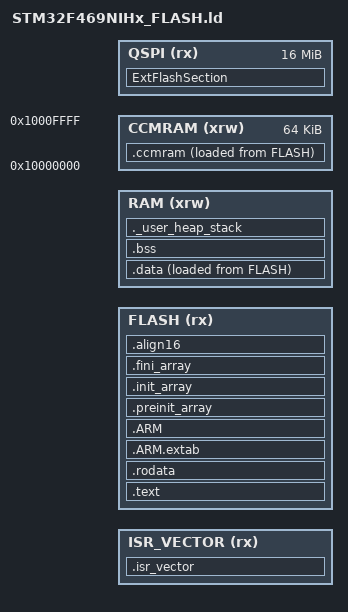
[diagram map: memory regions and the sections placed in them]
/*
*****************************************************************************
**

**  File        : LinkerScript.ld
**
**  Abstract    : Linker script for STM32F469NIHx Device with
**                2048KByte FLASH, 256KByte RAM
**
**                Set heap size, stack size and stack location according
**                to application requirements.
**
**                Set memory bank area and size if external memory is used.
**
**  Target      : STMicroelectronics STM32
**
**
**  Distribution: The file is distributed as is, without any warranty
**                of any kind.
**
**  (c)Copyright Ac6.
**  You may use this file as-is or modify it according to the needs of your
**  project. Distribution of this file (unmodified or modified) is not
**  permitted. Ac6 permit registered System Workbench for MCU users the
**  rights to distribute the assembled, compiled & linked contents of this
**  file as part of an application binary file, provided that it is built
**  using the System Workbench for MCU toolchain.
**
*****************************************************************************
*/

/* Entry Point */
ENTRY(Reset_Handler)

INCLUDE stm32-secure-patching-bootloader-linker-gcc_DISCO-F469I_v1.4.0.ld

/* Highest address of the user mode stack */
_estack = STM32_SECURE_PATCHING_BOOTLOADER_RAM_TOP;    /* end of RAM */
/* Generate a link error if heap and stack don't fit into RAM */
_Min_Heap_Size = 0x200;      /* required amount of heap  */
_Min_Stack_Size = 0x400; /* required amount of stack */

/* Specific ROM/RAM UserApp definition */
APPLI_region_intvec_start__  = STM32_SECURE_PATCHING_BOOTLOADER_SLOT0_START + 0x200;
APPLI_region_ROM_start    = STM32_SECURE_PATCHING_BOOTLOADER_SLOT0_START  + VECTOR_SIZE + 0x200;
APPLI_region_ROM_length   = STM32_SECURE_PATCHING_BOOTLOADER_SLOT0_END - APPLI_region_ROM_start + 1;
APPLI_region_RAM_start    = STM32_SECURE_PATCHING_BOOTLOADER_RAM_START;
APPLI_region_RAM_length    = STM32_SECURE_PATCHING_BOOTLOADER_RAM_TOP - APPLI_region_RAM_start;

/* Specify the memory areas */
MEMORY
{
ISR_VECTOR (rx)   : ORIGIN = APPLI_region_intvec_start__, LENGTH = VECTOR_SIZE
FLASH (rx)      : ORIGIN = APPLI_region_ROM_start, LENGTH = APPLI_region_ROM_length
RAM (xrw)      : ORIGIN = APPLI_region_RAM_start, LENGTH = APPLI_region_RAM_length
CCMRAM (xrw)      : ORIGIN = 0x10000000, LENGTH = 64K
QSPI (rx)         : ORIGIN = STM32_SECURE_PATCHING_BOOTLOADER_MULTISEG_START, LENGTH = 16M
}

/* Define output sections */
SECTIONS
{
  /* The startup code goes first into FLASH */
  .isr_vector :
  {
    . = ALIGN(8);
    KEEP(*(.isr_vector)) /* Startup code */
    FILL(0);
    . = ORIGIN(ISR_VECTOR) + LENGTH(ISR_VECTOR) - 1;
    BYTE(0)
    . = ALIGN(8);
  } >ISR_VECTOR

  /* The program code and other data goes into FLASH */
  .text :
  {
    . = ALIGN(4);
    *(.text)           /* .text sections (code) */
    *(.text*)          /* .text* sections (code) */
    *(.glue_7)         /* glue arm to thumb code */
    *(.glue_7t)        /* glue thumb to arm code */
    *(.eh_frame)

    KEEP (*(.init))
    KEEP (*(.fini))

    . = ALIGN(4);
    _etext = .;        /* define a global symbols at end of code */
  } >FLASH

  /* Constant data goes into FLASH */
  .rodata :
  {
    . = ALIGN(4);
    *(.rodata)         /* .rodata sections (constants, strings, etc.) */
    *(.rodata*)        /* .rodata* sections (constants, strings, etc.) */
    . = ALIGN(4);
  } >FLASH

  .ARM.extab   : { *(.ARM.extab* .gnu.linkonce.armextab.*) } >FLASH
  .ARM : {
    __exidx_start = .;
    *(.ARM.exidx*)
    __exidx_end = .;
  } >FLASH

  .preinit_array     :
  {
    PROVIDE_HIDDEN (__preinit_array_start = .);
    KEEP (*(.preinit_array*))
    PROVIDE_HIDDEN (__preinit_array_end = .);
  } >FLASH
  .init_array :
  {
    PROVIDE_HIDDEN (__init_array_start = .);
    KEEP (*(SORT(.init_array.*)))
    KEEP (*(.init_array*))
    PROVIDE_HIDDEN (__init_array_end = .);
  } >FLASH
  .fini_array :
  {
    PROVIDE_HIDDEN (__fini_array_start = .);
    KEEP (*(SORT(.fini_array.*)))
    KEEP (*(.fini_array*))
    PROVIDE_HIDDEN (__fini_array_end = .);
  } >FLASH

  /* used by the startup to initialize data */
  _sidata = LOADADDR(.data);

  /* Initialized data sections goes into RAM, load LMA copy after code */
  .data : 
  {
    . = ALIGN(4);
    _sdata = .;        /* create a global symbol at data start */
    *(.data)           /* .data sections */
    *(.data*)          /* .data* sections */

    . = ALIGN(4);
    _edata = .;        /* define a global symbol at data end */
  } >RAM AT> FLASH

  _siccmram = LOADADDR(.ccmram);

  /* CCM-RAM section 
  * 
  * IMPORTANT NOTE! 
  * If initialized variables will be placed in this section,
  * the startup code needs to be modified to copy the init-values.  
  */
  .ccmram :
  {
    . = ALIGN(4);
    _sccmram = .;       /* create a global symbol at ccmram start */
    *(.ccmram)
    *(.ccmram*)
    
    . = ALIGN(4);
    _eccmram = .;       /* create a global symbol at ccmram end */
  } >CCMRAM AT> FLASH

   /* Extra ROM section (last one) to make sure the binary size is a multiple of the AES block size (16 bytes) */
  .align16 :
  {
    . = . + 1;         /* _edata=. is aligned on 8 bytes so could be aligned on 16 bytes: add 1 byte gap */
    . = ALIGN(16) - 1; /* increment the location counter until next 16 bytes aligned address (-1 byte)   */
    BYTE(0);           /* allocate 1 byte (value is 0) to be a multiple of 16 bytes                      */
  } > FLASH
  
  /* Uninitialized data section */
  . = ALIGN(4);
  .bss :
  {
    /* This is used by the startup in order to initialize the .bss section */
    _sbss = .;         /* define a global symbol at bss start */
    __bss_start__ = _sbss;
    *(.bss)
    *(.bss*)
    *(COMMON)

    . = ALIGN(4);
    _ebss = .;         /* define a global symbol at bss end */
    __bss_end__ = _ebss;
  } >RAM

  /* User_heap_stack section, used to check that there is enough RAM left */
  ._user_heap_stack :
  {
    . = ALIGN(8);
    PROVIDE ( end = . );
    PROVIDE ( _end = . );
    . = . + _Min_Heap_Size;
    . = . + _Min_Stack_Size;
    . = ALIGN(8);
  } >RAM

  

  /* Remove information from the standard libraries */
  /DISCARD/ :
  {
    libc.a ( * )
    libm.a ( * )
    libgcc.a ( * )
  }

  .ARM.attributes 0 : { *(.ARM.attributes) }
  
  /* Section for placement of resources into QSPI segment 
   * This is not contiguous with the "ROM" segment, but must also be aligned
   * to 16 bytes for AES requirement.
   */
  ExtFlashSection : 
  { 
    *(ExtFlashSection) 

    . = . + 1;         /* _edata=. is aligned on 8 bytes so could be aligned on 16 bytes: add 1 byte gap */
    . = ALIGN(16) - 1; /* increment the location counter until next 16 bytes aligned address (-1 byte)   */
    BYTE(0);           /* allocate 1 byte (value is 0) to be a multiple of 16 bytes                      */
  } >QSPI 
}


